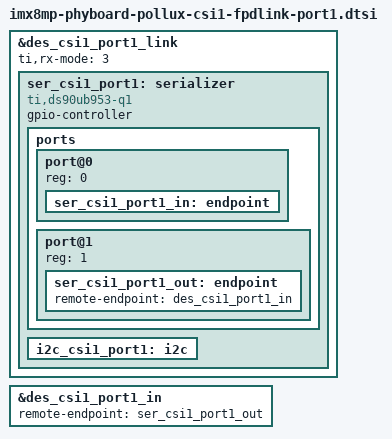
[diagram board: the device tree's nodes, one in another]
// SPDX-License-Identifier: (GPL-2.0+ OR MIT)
/*
 * Copyright (C) 2022 PHYTEC Messtechnik GmbH
 * Author: Stefan Riedmueller <s.riedmueller@phytec.de>
 */

/dts-v1/;
/plugin/;

#include "imx8mp-phyboard-pollux-csi1-fpdlink.dtsi"

&des_csi1_port1_link {
	ti,rx-mode = <3>;

	ser_csi1_port1: serializer {
		compatible = "ti,ds90ub953-q1";

		gpio-controller;
		#gpio-cells = <2>;

		#clock-cells = <0>;

		ports {
			#address-cells = <0x1>;
			#size-cells = <0x0>;
			port@0 {
				reg = <0>;
				ser_csi1_port1_in: endpoint {};
			};

			port@1 {
				reg = <1>;
				ser_csi1_port1_out: endpoint {
					remote-endpoint = <&des_csi1_port1_in>;
				};
			};
		};

		i2c_csi1_port1: i2c {
			#address-cells = <1>;
			#size-cells = <0>;
		};
	};
};

&des_csi1_port1_in {
	remote-endpoint = <&ser_csi1_port1_out>;
};
